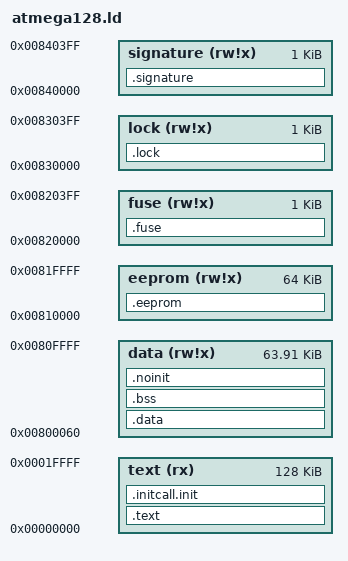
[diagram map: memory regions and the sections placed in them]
/* MIT License

Copyright (c) 2023 PlainOS

Permission is hereby granted, free of charge, to any person obtaining a copy
of this software and associated documentation files (the "Software"), to deal
in the Software without restriction, including without limitation the rights
to use, copy, modify, merge, publish, distribute, sublicense, and/or sell
copies of the Software, and to permit persons to whom the Software is
furnished to do so, subject to the following conditions:

The above copyright notice and this permission notice shall be included in all
copies or substantial portions of the Software.

THE SOFTWARE IS PROVIDED "AS IS", WITHOUT WARRANTY OF ANY KIND, EXPRESS OR
IMPLIED, INCLUDING BUT NOT LIMITED TO THE WARRANTIES OF MERCHANTABILITY,
FITNESS FOR A PARTICULAR PURPOSE AND NONINFRINGEMENT. IN NO EVENT SHALL THE
AUTHORS OR COPYRIGHT HOLDERS BE LIABLE FOR ANY CLAIM, DAMAGES OR OTHER
LIABILITY, WHETHER IN AN ACTION OF CONTRACT, TORT OR OTHERWISE, ARISING FROM,
OUT OF OR IN CONNECTION WITH THE SOFTWARE OR THE USE OR OTHER DEALINGS IN THE
SOFTWARE.
*/

#include <kernel/sections.h>
/* Default linker script, for normal executables */
OUTPUT_FORMAT("elf32-avr","elf32-avr","elf32-avr")
OUTPUT_ARCH(avr:51)
MEMORY
{
  text      (rx)   : ORIGIN = 0, LENGTH = 128K
  data      (rw!x) : ORIGIN = 0x800060, LENGTH = 0xffa0
  eeprom    (rw!x) : ORIGIN = 0x810000, LENGTH = 64K
  fuse      (rw!x) : ORIGIN = 0x820000, LENGTH = 1K
  lock      (rw!x) : ORIGIN = 0x830000, LENGTH = 1K
  signature (rw!x) : ORIGIN = 0x840000, LENGTH = 1K
}
SECTIONS
{
  /* Internal text space or external memory.  */
  .text   :
  {
    *(.vectors)
    KEEP(*(.vectors))
    /* For data that needs to reside in the lower 64k of progmem.  */
    *(.progmem.gcc*)
    *(.progmem*)
    . = ALIGN(2);
     __trampolines_start = . ;
    /* The jump trampolines for the 16-bit limited relocs will reside here.  */
    *(.trampolines)
    *(.trampolines*)
     __trampolines_end = . ;
    /* For future tablejump instruction arrays for 3 byte pc devices.
       We don't relax jump/call instructions within these sections.  */
    *(.jumptables)
    *(.jumptables*)
    /* For code that needs to reside in the lower 128k progmem.  */
    *(.lowtext)
    *(.lowtext*)
     __ctors_start = . ;
     *(.ctors)
     __ctors_end = . ;
     __dtors_start = . ;
     *(.dtors)
     __dtors_end = . ;
    KEEP(SORT(*)(.ctors))
    KEEP(SORT(*)(.dtors))
    /* From this point on, we don't bother about wether the insns are
       below or above the 16 bits boundary.  */
    *(.init0)  /* Start here after reset.  */
    KEEP (*(.init0))
    *(.init1)
    KEEP (*(.init1))
    *(.init2)  /* Clear __zero_reg__, set up stack pointer.  */
    KEEP (*(.init2))
    *(.init3)
    KEEP (*(.init3))
    *(.init4)  /* Initialize data and BSS.  */
    KEEP (*(.init4))
    *(.init5)
    KEEP (*(.init5))
    *(.init6)  /* C++ constructors.  */
    KEEP (*(.init6))
    *(.init7)
    KEEP (*(.init7))
    *(.init8)
    KEEP (*(.init8))
    *(.init9)  /* Call main().  */
    KEEP (*(.init9))
    *(.text)
    . = ALIGN(2);
    *(.text.*)
    . = ALIGN(2);
    *(.fini9)  /* _exit() starts here.  */
    KEEP (*(.fini9))
    *(.fini8)
    KEEP (*(.fini8))
    *(.fini7)
    KEEP (*(.fini7))
    *(.fini6)  /* C++ destructors.  */
    KEEP (*(.fini6))
    *(.fini5)
    KEEP (*(.fini5))
    *(.fini4)
    KEEP (*(.fini4))
    *(.fini3)
    KEEP (*(.fini3))
    *(.fini2)
    KEEP (*(.fini2))
    *(.fini1)
    KEEP (*(.fini1))
    *(.fini0)  /* Infinite loop after program termination.  */
    KEEP (*(.fini0))
     _etext = . ;
  }  > text

   .initcall.init :
   {
     . = ALIGN(4);
     INIT_CALLS
     . = ALIGN(4);
   } >text

  .data	  : AT (ADDR (.text) + SIZEOF (.text))
  {
     PROVIDE (__data_start = .) ;
    *(.data)
    *(.data*)
    *(.rodata)  /* We need to include .rodata here if gcc is used */
    *(.rodata*) /* with -fdata-sections.  */
    *(.gnu.linkonce.d*)
    . = ALIGN(2);
     _edata = . ;
     PROVIDE (__data_end = .) ;
  }  > data
  .bss   : AT (ADDR (.bss))
  {
     PROVIDE (__bss_start = .) ;
    *(.bss)
    *(.bss*)
    *(COMMON)
     PROVIDE (__bss_end = .) ;
  }  > data
   __data_load_start = LOADADDR(.data);
   __data_load_end = __data_load_start + SIZEOF(.data);
  /* Global data not cleared after reset.  */
  .noinit  :
  {
     PROVIDE (__noinit_start = .) ;
    *(.noinit*)
     PROVIDE (__noinit_end = .) ;
     _end = . ;
     PROVIDE (__heap_start = .) ;
  }  > data
  .eeprom  :
  {
    *(.eeprom*)
     __eeprom_end = . ;
  }  > eeprom
  .fuse  :
  {
    KEEP(*(.fuse))
    KEEP(*(.lfuse))
    KEEP(*(.hfuse))
    KEEP(*(.efuse))
  }  > fuse
  .lock  :
  {
    KEEP(*(.lock*))
  }  > lock
  .signature  :
  {
    KEEP(*(.signature*))
  }  > signature
}
